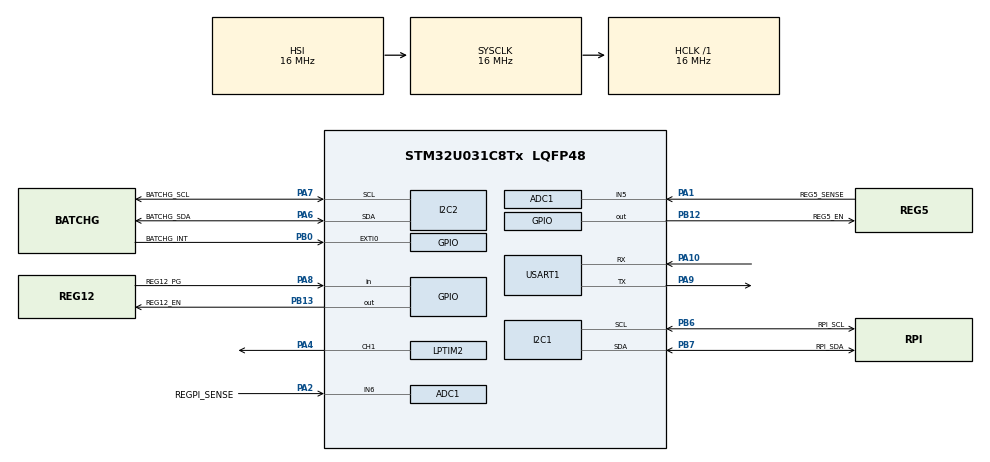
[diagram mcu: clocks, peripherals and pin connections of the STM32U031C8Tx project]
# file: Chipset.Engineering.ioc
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ADC1.Channel-0\#ChannelRegularConversion=ADC_CHANNEL_5
ADC1.Channel-1\#ChannelRegularConversion=ADC_CHANNEL_6
ADC1.ContinuousConvMode=ENABLE
ADC1.NbrOfConversion=2
ADC1.NbrOfConversionFlag=1
ADC1.Rank-0\#ChannelRegularConversion=1
ADC1.Rank-1\#ChannelRegularConversion=2
ADC1.RankArg-0\#ChannelRegularConversion=ADC_REGULAR_RANK_1
ADC1.RankArg-1\#ChannelRegularConversion=ADC_REGULAR_RANK_2
ADC1.SamplingTime-0\#ChannelRegularConversion=ADC_SAMPLINGTIME_COMMON_1
ADC1.SamplingTime-1\#ChannelRegularConversion=ADC_SAMPLINGTIME_COMMON_1
ADC1.SelectedChannel=ADC_CHANNEL_5|ADC_CHANNEL_6
ADC1.master=1
Dma.ADC1.0.Direction=DMA_PERIPH_TO_MEMORY
Dma.ADC1.0.EventEnable=DISABLE
Dma.ADC1.0.Instance=DMA1_Channel6
Dma.ADC1.0.MemDataAlignment=DMA_MDATAALIGN_HALFWORD
Dma.ADC1.0.MemInc=DMA_MINC_ENABLE
Dma.ADC1.0.Mode=DMA_CIRCULAR
Dma.ADC1.0.PeriphDataAlignment=DMA_PDATAALIGN_HALFWORD
Dma.ADC1.0.PeriphInc=DMA_PINC_DISABLE
Dma.ADC1.0.Polarity=HAL_DMAMUX_REQ_GEN_RISING
Dma.ADC1.0.Priority=DMA_PRIORITY_LOW
Dma.ADC1.0.RequestNumber=1
Dma.ADC1.0.SignalID=NONE
Dma.ADC1.0.SyncEnable=DISABLE
Dma.ADC1.0.SyncPolarity=HAL_DMAMUX_SYNC_NO_EVENT
Dma.ADC1.0.SyncRequestNumber=1
Dma.ADC1.0.SyncSignalID=NONE
Dma.I2C1_RX.3.Direction=DMA_PERIPH_TO_MEMORY
Dma.I2C1_RX.3.EventEnable=DISABLE
Dma.I2C1_RX.3.Instance=DMA1_Channel1
Dma.I2C1_RX.3.MemDataAlignment=DMA_MDATAALIGN_BYTE
Dma.I2C1_RX.3.MemInc=DMA_MINC_ENABLE
Dma.I2C1_RX.3.Mode=DMA_NORMAL
Dma.I2C1_RX.3.PeriphDataAlignment=DMA_PDATAALIGN_BYTE
Dma.I2C1_RX.3.PeriphInc=DMA_PINC_DISABLE
Dma.I2C1_RX.3.Polarity=HAL_DMAMUX_REQ_GEN_RISING
Dma.I2C1_RX.3.Priority=DMA_PRIORITY_LOW
Dma.I2C1_RX.3.RequestNumber=1
Dma.I2C1_RX.3.SignalID=NONE
Dma.I2C1_RX.3.SyncEnable=DISABLE
Dma.I2C1_RX.3.SyncPolarity=HAL_DMAMUX_SYNC_NO_EVENT
Dma.I2C1_RX.3.SyncRequestNumber=1
Dma.I2C1_RX.3.SyncSignalID=NONE
Dma.I2C1_TX.4.Direction=DMA_MEMORY_TO_PERIPH
Dma.I2C1_TX.4.EventEnable=DISABLE
Dma.I2C1_TX.4.Instance=DMA1_Channel2
Dma.I2C1_TX.4.MemDataAlignment=DMA_MDATAALIGN_BYTE
Dma.I2C1_TX.4.MemInc=DMA_MINC_ENABLE
Dma.I2C1_TX.4.Mode=DMA_NORMAL
Dma.I2C1_TX.4.PeriphDataAlignment=DMA_PDATAALIGN_BYTE
Dma.I2C1_TX.4.PeriphInc=DMA_PINC_DISABLE
Dma.I2C1_TX.4.Polarity=HAL_DMAMUX_REQ_GEN_RISING
Dma.I2C1_TX.4.Priority=DMA_PRIORITY_LOW
Dma.I2C1_TX.4.RequestNumber=1
Dma.I2C1_TX.4.SignalID=NONE
Dma.I2C1_TX.4.SyncEnable=DISABLE
Dma.I2C1_TX.4.SyncPolarity=HAL_DMAMUX_SYNC_NO_EVENT
Dma.I2C1_TX.4.SyncRequestNumber=1
Dma.I2C1_TX.4.SyncSignalID=NONE
Dma.I2C2_RX.1.Direction=DMA_PERIPH_TO_MEMORY
Dma.I2C2_RX.1.EventEnable=DISABLE
Dma.I2C2_RX.1.Instance=DMA1_Channel3
Dma.I2C2_RX.1.MemDataAlignment=DMA_MDATAALIGN_BYTE
Dma.I2C2_RX.1.MemInc=DMA_MINC_ENABLE
Dma.I2C2_RX.1.Mode=DMA_NORMAL
Dma.I2C2_RX.1.PeriphDataAlignment=DMA_PDATAALIGN_BYTE
Dma.I2C2_RX.1.PeriphInc=DMA_PINC_DISABLE
Dma.I2C2_RX.1.Polarity=HAL_DMAMUX_REQ_GEN_RISING
Dma.I2C2_RX.1.Priority=DMA_PRIORITY_LOW
Dma.I2C2_RX.1.RequestNumber=1
Dma.I2C2_RX.1.SignalID=NONE
Dma.I2C2_RX.1.SyncEnable=DISABLE
Dma.I2C2_RX.1.SyncPolarity=HAL_DMAMUX_SYNC_NO_EVENT
Dma.I2C2_RX.1.SyncRequestNumber=1
Dma.I2C2_RX.1.SyncSignalID=NONE
Dma.I2C2_TX.2.Direction=DMA_MEMORY_TO_PERIPH
Dma.I2C2_TX.2.EventEnable=DISABLE
Dma.I2C2_TX.2.Instance=DMA1_Channel4
Dma.I2C2_TX.2.MemDataAlignment=DMA_MDATAALIGN_BYTE
Dma.I2C2_TX.2.MemInc=DMA_MINC_ENABLE
Dma.I2C2_TX.2.Mode=DMA_NORMAL
Dma.I2C2_TX.2.PeriphDataAlignment=DMA_PDATAALIGN_BYTE
Dma.I2C2_TX.2.PeriphInc=DMA_PINC_DISABLE
Dma.I2C2_TX.2.Polarity=HAL_DMAMUX_REQ_GEN_RISING
Dma.I2C2_TX.2.Priority=DMA_PRIORITY_LOW
Dma.I2C2_TX.2.RequestNumber=1
Dma.I2C2_TX.2.SignalID=NONE
Dma.I2C2_TX.2.SyncEnable=DISABLE
Dma.I2C2_TX.2.SyncPolarity=HAL_DMAMUX_SYNC_NO_EVENT
Dma.I2C2_TX.2.SyncRequestNumber=1
Dma.I2C2_TX.2.SyncSignalID=NONE
Dma.Request0=ADC1
Dma.Request1=I2C2_RX
Dma.Request2=I2C2_TX
Dma.Request3=I2C1_RX
Dma.Request4=I2C1_TX
I2C1.Timing=0x00303D5B
I2C2.Timing=0x00303D5B
LPTIM2.ClockPrescaler=LPTIM_PRESCALER_DIV128
LPTIM2.OCPulse_1=32000
Mcu.Family=STM32U0
Mcu.Name=STM32U031C8Tx
Mcu.Package=LQFP48
NVIC.DMA1_Ch4_7_DMA2_Ch1_5_DMAMUX_OVR_IRQn=true\:0\:0\:false\:false\:true\:false\:true\:true
NVIC.DMA1_Channel1_IRQn=true\:0\:0\:false\:false\:true\:false\:true\:true
NVIC.DMA1_Channel2_3_IRQn=true\:0\:0\:false\:false\:true\:false\:true\:true
NVIC.I2C1_IRQn=true\:0\:0\:false\:false\:true\:true\:true\:true
NVIC.I2C2_3_IRQn=true\:0\:0\:false\:false\:true\:true\:true\:true
NVIC.PriorityGroup=NVIC_PRIORITYGROUP_2
PA1.GPIO_Label=REG5_SENSE
PA1.Mode=IN5
PA1.Signal=ADC1_IN5
PA10.Mode=Asynchronous
PA10.Signal=USART1_RX
PA13\ (SWDIO).Mode=Serial_Wire
PA13\ (SWDIO).Signal=DEBUG_JTMS-SWDIO
PA14\ (SWCLK).Mode=Serial_Wire
PA14\ (SWCLK).Signal=DEBUG_JTCK-SWCLK
PA2.GPIO_Label=REGPI_SENSE
PA2.Mode=IN6
PA2.Signal=ADC1_IN6
PA4.Signal=S_LPTIM2_CH1
PA6.GPIO_Label=BATCHG_SDA
PA6.GPIO_Pu=GPIO_PULLUP
PA6.Mode=I2C
PA6.Signal=I2C2_SDA
PA7.GPIO_Label=BATCHG_SCL
PA7.GPIO_Pu=GPIO_PULLUP
PA7.Mode=I2C
PA7.Signal=I2C2_SCL
PA8.GPIO_Label=REG12_PG
PA8.Signal=GPIO_Input
PA9.Mode=Asynchronous
PA9.Signal=USART1_TX
PB0.GPIO_Label=BATCHG_INT
PB0.Signal=GPXTI0
PB12.GPIO_Label=REG5_EN
PB12.Signal=GPIO_Output
PB13.GPIO_Label=REG12_EN
PB13.Signal=GPIO_Output
PB6.GPIO_Label=RPI_SCL
PB6.GPIO_Pu=GPIO_PULLUP
PB6.Mode=I2C
PB6.Signal=I2C1_SCL
PB7.GPIO_Label=RPI_SDA
PB7.GPIO_Pu=GPIO_PULLUP
PB7.Mode=I2C
PB7.Signal=I2C1_SDA
ProjectManager.HeapSize=0x200
ProjectManager.StackSize=0x400
ProjectManager.TargetToolchain=CMake
RCC.AHBFreq_Value=16000000
RCC.CortexFreq_Value=16000000
RCC.HCLKFreq_Value=16000000
RCC.HSE_VALUE=4000000
RCC.HSI48_VALUE=48000000
RCC.HSI_VALUE=16000000
RCC.LSE_VALUE=32768
RCC.MSI_VALUE=4000000
RCC.SYSCLKFreq_VALUE=16000000
RCC.VCOOutputFreq_Value=64000000
SH.S_LPTIM2_CH1.0=LPTIM2_CH1,OutputIO_CH1
USART1.VirtualMode-Asynchronous=VM_ASYNC
VP_LPTIM2_VS_CH1.Mode=Channel_1_Active
VP_LPTIM2_VS_LPTIM_counterModeInternalClock.Mode=Counts__internal_clock_event_00
VP_PWR_VS_SECSignals.Mode=Security/Privilege
board=custom

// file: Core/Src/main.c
/* USER CODE BEGIN Header */
/**
  ******************************************************************************
  * @file           : main.c
  * @brief          : Main program body
  ******************************************************************************
  * @attention
  *
  * Copyright (c) 2025 STMicroelectronics.
  * All rights reserved.
  *
  * This software is licensed under terms that can be found in the LICENSE file
  * in the root directory of this software component.
  * If no LICENSE file comes with this software, it is provided AS-IS.
  *
  ******************************************************************************
  */
/* USER CODE END Header */
#include "main.h"
#include "adc.h"
#include "dma.h"
#include "i2c.h"
#include "lptim.h"
#include "usart.h"
#include "gpio.h"

/* USER CODE BEGIN Includes */
#include "PiSubmarine/Chipset/Engineering/AppMain.h"
/* USER CODE END Includes */

void SystemClock_Config(void);

int main(void)
{

  /* MCU Configuration--------------------------------------------------------*/

  /* Reset of all peripherals, Initializes the Flash interface and the Systick. */
  HAL_Init();

  /* Configure the system clock */
  SystemClock_Config();

  /* Initialize all configured peripherals */
  MX_GPIO_Init();
  MX_DMA_Init();
  MX_I2C2_Init();
  MX_USART1_UART_Init();
  MX_LPTIM2_Init();
  MX_ADC1_Init();
  MX_I2C1_Init();
  /* USER CODE BEGIN 2 */
  AppMainRun(NULL);
  /* USER CODE END 2 */

  /* Infinite loop */
  while (1)
  {

  }
}

void SystemClock_Config(void)
{
  RCC_OscInitTypeDef RCC_OscInitStruct = {0};
  RCC_ClkInitTypeDef RCC_ClkInitStruct = {0};

  /** Configure the main internal regulator output voltage
  */
  HAL_PWREx_ControlVoltageScaling(PWR_REGULATOR_VOLTAGE_SCALE2);

  /** Initializes the RCC Oscillators according to the specified parameters
  * in the RCC_OscInitTypeDef structure.
  */
  RCC_OscInitStruct.OscillatorType = RCC_OSCILLATORTYPE_HSI;
  RCC_OscInitStruct.HSIState = RCC_HSI_ON;
  RCC_OscInitStruct.HSICalibrationValue = RCC_HSICALIBRATION_DEFAULT;
  RCC_OscInitStruct.PLL.PLLState = RCC_PLL_NONE;
  if (HAL_RCC_OscConfig(&RCC_OscInitStruct) != HAL_OK)
  {
    Error_Handler();
  }

  /** Initializes the CPU, AHB and APB buses clocks
  */
  RCC_ClkInitStruct.ClockType = RCC_CLOCKTYPE_HCLK|RCC_CLOCKTYPE_SYSCLK
                              |RCC_CLOCKTYPE_PCLK1;
  RCC_ClkInitStruct.SYSCLKSource = RCC_SYSCLKSOURCE_HSI;
  RCC_ClkInitStruct.AHBCLKDivider = RCC_SYSCLK_DIV1;
  RCC_ClkInitStruct.APB1CLKDivider = RCC_HCLK_DIV1;

  if (HAL_RCC_ClockConfig(&RCC_ClkInitStruct, FLASH_LATENCY_1) != HAL_OK)
  {
    Error_Handler();
  }
}

void Error_Handler(void)
{
  __disable_irq();
  while (1)
  {
  }
}
